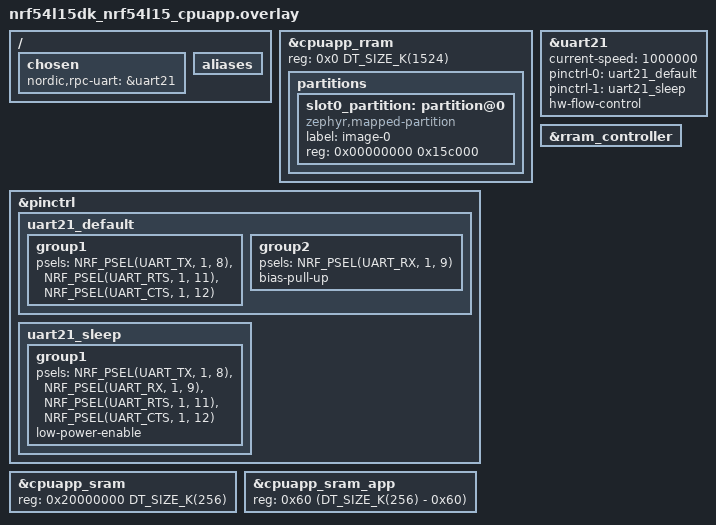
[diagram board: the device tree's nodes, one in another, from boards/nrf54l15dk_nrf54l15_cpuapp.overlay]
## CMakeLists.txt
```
#
# Copyright (c) 2026 Nordic Semiconductor ASA
#
# SPDX-License-Identifier: LicenseRef-Nordic-5-Clause
#

cmake_minimum_required(VERSION 3.20.0)

find_package(Zephyr REQUIRED HINTS $ENV{ZEPHYR_BASE})
project(dect_rpc)

target_sources(app PRIVATE src/main.c)
target_sources_ifdef(CONFIG_SAMPLE_DECT_RPC_CLIENT_IPERF3 app PRIVATE src/iperf3_shell.c)
```

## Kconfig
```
#
# Copyright (c) 2026 Nordic Semiconductor ASA
#
# SPDX-License-Identifier: LicenseRef-Nordic-5-Clause
#

menu "DECT NR+ RPC sample configuration"

config SAMPLE_DECT_RPC_CLIENT_IPERF3
	bool "iPerf3 (shell command)"
	select NRF_IPERF3
	help
	  Enable the ``iperf3`` shell command.

endmenu

source "Kconfig.zephyr"
```

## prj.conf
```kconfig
# DECT NR+ RPC sample — default role is client (no DECT modem on this device).
CONFIG_DECT_NR_RPC=y
CONFIG_DECT_NR_RPC_CLIENT=y
CONFIG_DECT_NR_RPC_NET_IF=y
CONFIG_NRF_RPC_UART_TRANSPORT=y
CONFIG_DECT_NR_RPC_UART_TRANSPORT=y

CONFIG_DECT_NR_RPC_CLIENT_IFACE_NAME="dect0"

# UART RPC RX ring (RAM). Use rpc-large-rx.conf (8 KiB) if bursts drop after connect.
CONFIG_NRF_RPC_UART_RX_RINGBUF_SIZE=4096

CONFIG_NRF_RPC_CBOR=y
CONFIG_NRF_RPC_ZCBOR_BACKUPS=1
CONFIG_NRF_RPC_THREAD_STACK_SIZE=4096
CONFIG_NRF_RPC_THREAD_PRIORITY=0

CONFIG_NRF_RPC_UART_RELIABLE=n
# 250 ms is too short for verbose "dect run sett -r" (many SHELL_LINE events + cmd RSP).
CONFIG_NRF_RPC_RESPONSE_TIMEOUT=400

# Client is follower: do not send group init; wait for server to send it.
CONFIG_NRF_RPC_GROUP_DEFAULT_INITIATOR=n
CONFIG_NRF_RPC_GROUP_INIT_WAIT_TIME=-1

CONFIG_UART_LINE_CTRL=y
CONFIG_UART_INTERRUPT_DRIVEN=y

# Networking
CONFIG_NETWORKING=y
CONFIG_NET_NATIVE=y
CONFIG_NET_IPV6=y
CONFIG_NET_MGMT_EVENT_STACK_SIZE=2048
CONFIG_NET_CONNECTION_MANAGER_MONITOR_STACK_SIZE=2048
CONFIG_DECT_NR_RPC_CONN_MGR=y
CONFIG_NET_IPV4=n
CONFIG_NET_SOCKETS=y
CONFIG_NET_SOCKETS_OFFLOAD=n
CONFIG_NET_MAX_CONN=6

CONFIG_NET_IF_UNICAST_IPV6_ADDR_COUNT=3
CONFIG_NET_IF_MAX_IPV6_COUNT=8
CONFIG_NET_INTERFACE_NAME=y

CONFIG_ZVFS_POLL_MAX=10

CONFIG_NET_BUF=y
CONFIG_NET_PKT_RX_COUNT=4
CONFIG_NET_BUF_RX_COUNT=8
CONFIG_NET_PKT_TX_COUNT=4
CONFIG_NET_BUF_TX_COUNT=8

CONFIG_HEAP_MEM_POOL_SIZE=2048

CONFIG_SHELL_STACK_SIZE=3072

# Optional: server.conf, dns.conf, ping.conf, iperf3-*.conf

CONFIG_LOG=y
CONFIG_NET_LOG=y
CONFIG_NRF_RPC_TR_LOG_LEVEL_INF=y
CONFIG_NRF_RPC_LOG_LEVEL_INF=y

CONFIG_SHELL=y
CONFIG_SHELL_PROMPT_UART="dect_rpc_client:~$ "
CONFIG_SHELL_BACKEND_SERIAL=y
CONFIG_NET_SHELL=y
CONFIG_DECT_NR_RPC_CLIENT_SHELL=y

CONFIG_LOG_BACKEND_UART=n
CONFIG_LOG_PRINTK=n

CONFIG_ASSERT=y
CONFIG_ASSERT_MODULE_DEFAULT_LEVEL_VERBOSE=y
CONFIG_RESET_ON_FATAL_ERROR=n
CONFIG_EXTRA_EXCEPTION_INFO=y
CONFIG_NET_DECT_RPC_LOG_LEVEL_INF=y
```

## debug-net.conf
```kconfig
# Extra Kconfig fragment: Zephyr net stack debug logging (RPC client).
#
# Build from this sample directory (see README):
#   west build -p -b nrf9151dk/nrf9151/ns -- -DEXTRA_CONF_FILE=debug-net.conf

CONFIG_NET_LOG=y
CONFIG_NET_CORE_LOG_LEVEL_DBG=y
CONFIG_NET_CONN_LOG_LEVEL_DBG=y
CONFIG_NET_SOCKETS_LOG_LEVEL_DBG=y
CONFIG_NET_IPV6_LOG_LEVEL_DBG=y
CONFIG_NET_ICMPV6_LOG_LEVEL_DBG=y
```

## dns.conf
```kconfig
# Unicast DNS resolver (optional). Not needed for literal IPv6 or RPC-only tests.
# Combine with ping.conf for hostname ping.
#
# CONFIG_DNS_SERVER1 must be reachable from dect0 (UDP/53 forwarded over RPC to the
# server DECT iface, then routed on the DECT network). Public resolvers (e.g. Google)
# only work if the DECT parent/BR provides internet routing. In many lab setups, set
# DNS_SERVER1 to your BR/DECT DNS instead. Verify with: net dns <name>

CONFIG_DNS_RESOLVER=y
CONFIG_DNS_RESOLVER_AUTO_INIT=y
CONFIG_DNS_SERVER_IP_ADDRESSES=y
CONFIG_DNS_SERVER1="2001:4860:4860::8888"
CONFIG_NET_SOCKETS_DNS_TIMEOUT=10000
CONFIG_NET_SOCKETS_DNS_BACKOFF_INTERVAL=4000
```

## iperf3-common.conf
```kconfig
# iperf3 common configuration.
# Build from this directory, e.g.:
#   west build -p -b nrf9151dk/nrf9151/ns -- -DEXTRA_CONF_FILE="iperf3-common.conf;iperf3-tx.conf"
#
# Disables DNS/mDNS and other extras not needed for raw throughput tests.

CONFIG_SAMPLE_DECT_RPC_CLIENT_IPERF3=y

# Throughput: avoid periodic GET_ADDRS on the same UART as IF_SEND; use 8 KiB RX ring.
CONFIG_DECT_NR_RPC_ADDR_SYNC_INTERVAL_SEC=0
CONFIG_NRF_RPC_UART_RX_RINGBUF_SIZE=8192

CONFIG_NRF_RPC_THREAD_POOL_SIZE=5
CONFIG_NRF_RPC_CMD_CTX_POOL_SIZE=12

CONFIG_DNS_RESOLVER=n
CONFIG_DNS_SD=n
CONFIG_DNS_RESOLVER_AUTO_INIT=n
CONFIG_DNS_RESOLVER_CACHE=n
CONFIG_DNS_SERVER_IP_ADDRESSES=n
CONFIG_MDNS_RESOLVER=n
CONFIG_MDNS_RESPONDER=n
CONFIG_MDNS_RESPONDER_DNS_SD=n
CONFIG_NET_SOCKETS_PACKET=n
CONFIG_NET_SOCKETS_PACKET_DGRAM=n
CONFIG_NET_SOCKETS_INET_RAW=n

CONFIG_NRF_IPERF3_HOST_NAME="nrf-dect-rpc-client-iperf3"
CONFIG_NRF_IPERF3_RESULTS_WAIT_TIME=180
CONFIG_NRF_IPERF3_NONBLOCKING_CLIENT_CHANGES=n

CONFIG_NET_IPV4=n
CONFIG_NET_IPV6=y
CONFIG_NET_IP_ADDR_CHECK=n
CONFIG_NET_IF_MAX_IPV6_COUNT=4

CONFIG_NET_TCP=y
CONFIG_NET_TCP_WORKQ_STACK_SIZE=2048
CONFIG_NET_TCP_INIT_RETRANSMISSION_TIMEOUT=6000
CONFIG_NET_TCP_RETRY_COUNT=6
CONFIG_NET_TCP_ISN_RFC6528=n

CONFIG_POSIX_API=y
CONFIG_GETOPT_LONG=y
CONFIG_CJSON_LIB=y
CONFIG_ZVFS_POLL_MAX=12
CONFIG_NET_MAX_CONTEXTS=10
CONFIG_NET_MAX_CONN=10

CONFIG_NET_CONTEXT_RCVTIMEO=y
CONFIG_NET_CONTEXT_SNDTIMEO=y

CONFIG_NET_BUF=y
CONFIG_NET_BUF_DATA_SIZE=128
CONFIG_NET_BUF_POOL_USAGE=y
CONFIG_NET_TC_RX_COUNT=0

# iperf3 uses libc malloc(); UART RPC TX uses k_malloc per frame (~header + CBOR + payload).
CONFIG_COMMON_LIBC_MALLOC_ARENA_SIZE=18432
CONFIG_HEAP_MEM_POOL_SIZE=24576
CONFIG_MAIN_STACK_SIZE=4096
CONFIG_SHELL_CMD_BUFF_SIZE=2048
# iperf_main() runs on the shell thread; default 2048 overflows (same as DeSh).
CONFIG_SHELL_STACK_SIZE=9216

CONFIG_SYS_HEAP_RUNTIME_STATS=y

CONFIG_NRF_RPC_TR_LOG_LEVEL_INF=y
CONFIG_NRF_RPC_LOG_LEVEL_WRN=y
CONFIG_NET_DECT_RPC_LOG_LEVEL_WRN=y
```

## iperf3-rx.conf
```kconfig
# iperf3 RX configuration (iperf server / downlink-heavy).
# Use after :file:`iperf3-common.conf`.

CONFIG_NRF_IPERF3_HOST_NAME="nrf-dect-rpc-client-iperf3-rx"

CONFIG_NET_BUF_DATA_SIZE=256
CONFIG_NET_PKT_RX_COUNT=22
CONFIG_NET_BUF_RX_COUNT=48
CONFIG_NET_PKT_TX_COUNT=16
CONFIG_NET_BUF_TX_COUNT=32

CONFIG_NET_TCP_RECV_QUEUE_TIMEOUT=10000
```

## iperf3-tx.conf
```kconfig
# iperf3 TX configuration (iperf client / uplink-heavy).
# Use after :file:`iperf3-common.conf`.

CONFIG_NRF_IPERF3_HOST_NAME="nrf-dect-rpc-client-iperf3-tx"

CONFIG_NET_BUF_DATA_SIZE=256
CONFIG_NET_PKT_RX_COUNT=10
CONFIG_NET_BUF_RX_COUNT=20
CONFIG_NET_PKT_TX_COUNT=30
CONFIG_NET_BUF_TX_COUNT=60
```

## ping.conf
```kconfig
# ICMPv6 ping shell (DECT_ICMP_PING_LIB).
#
# Build: west build ... -- -DEXTRA_CONF_FILE="ping.conf;dns.conf"
#
# Literal IPv6 targets work without dns.conf; hostnames need dns.conf.

CONFIG_GETOPT_LONG=y
CONFIG_DECT_ICMP_PING_LIB=y
CONFIG_DECT_ICMP_PING_DEFAULT_IFACE="dect0"

# getaddrinfo (dest + src) and shell command parsing
CONFIG_HEAP_MEM_POOL_SIZE=3072
CONFIG_SHELL_STACK_SIZE=4096
CONFIG_SYSTEM_WORKQUEUE_STACK_SIZE=2048

CONFIG_NET_STATISTICS=y
```

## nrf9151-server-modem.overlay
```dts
/*
 * Copyright (c) 2026 Nordic Semiconductor ASA
 *
 * SPDX-License-Identifier: LicenseRef-Nordic-5-Clause
 *
 * Server-only nRF9151 layout: modem IPC SHMEM and non-secure application RAM.
 * Apply on top of the default (client) board overlay when building server.conf:
 *
 *   -DEXTRA_DTC_OVERLAY_FILE=nrf9151-server-modem.overlay
 *
 * Flash partitions come from the default board overlay (client layout).
 */

/delete-node/ &sram0_s;
/delete-node/ &sram0_ns;

&sram0 {
	sram0_s: sram@0 {
		reg = <0x0 0x8000>;
	};

	sram0_ns: sram@8000 {
		reg = <0x8000 0x38000>;
		#address-cells = <1>;
		#size-cells = <1>;
		ranges = <0x0 0x8000 0x38000>;

		sram0_ns_modem: sram0_ns@0 {
			reg = <0x0 0x47a8>;
			#address-cells = <1>;
			#size-cells = <1>;
			ranges = <0x0 0x0 0x47a8>;

			cpuapp_cpucell_ipc_shm_ctrl: sram0_ns_modem@0 {
				reg = <0x0 0x728>;
			};

			cpuapp_cpucell_ipc_shm_heap: sram0_ns_modem@728 {
				reg = <0x728 0x2080>;
			};

			cpucell_cpuapp_ipc_shm_heap: sram0_ns_modem@27a8 {
				reg = <0x27a8 0x2000>;
			};
		};

		sram0_ns_app: sram0_ns@47a8 {
			reg = <0x47a8 0x33858>;
		};
	};
};
```

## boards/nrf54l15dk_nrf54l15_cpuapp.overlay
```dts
/*
 * Copyright (c) 2026 Nordic Semiconductor ASA
 *
 * SPDX-License-Identifier: LicenseRef-Nordic-5-Clause
 *
 * RPC over UART21 @ 1 Mbps with HW flow control (nRF RPC serialization reference).
 *
 * nRF54L15 DK (application core) UART21: RX P1.09, TX P1.08, RTS P1.11, CTS P1.12.
 * Cross-connect to nRF9151 DK server RPC UART (P0.10–P0.13).
 *
 * Frees GPIO used by UART21 by removing buttons 1–3 from devicetree.
 */

/ {
	chosen {
		nordic,rpc-uart = &uart21;
	};

	aliases {
		/delete-property/ sw1;
		/delete-property/ sw2;
		/delete-property/ sw3;
	};
};

/delete-node/ &button1;
/delete-node/ &button2;
/delete-node/ &button3;
/delete-node/ &boot_partition;
/delete-node/ &slot0_partition;
/delete-node/ &slot1_partition;

&cpuapp_rram {
	reg = <0x0 DT_SIZE_K(1524)>;

	partitions {
		slot0_partition: partition@0 {
			compatible = "zephyr,mapped-partition";
			label = "image-0";
			reg = <0x00000000 0x15c000>;
		};
	};
};

&pinctrl {
	uart21_default: uart21_default {
		group1 {
			psels = <NRF_PSEL(UART_TX, 1, 8)>,
				<NRF_PSEL(UART_RTS, 1, 11)>,
				<NRF_PSEL(UART_CTS, 1, 12)>;
		};

		group2 {
			psels = <NRF_PSEL(UART_RX, 1, 9)>;
			bias-pull-up;
		};
	};

	uart21_sleep: uart21_sleep {
		group1 {
			psels = <NRF_PSEL(UART_TX, 1, 8)>,
				<NRF_PSEL(UART_RX, 1, 9)>,
				<NRF_PSEL(UART_RTS, 1, 11)>,
				<NRF_PSEL(UART_CTS, 1, 12)>;
			low-power-enable;
		};
	};
};

&uart21 {
	status = "okay";
	current-speed = <1000000>;
	pinctrl-0 = <&uart21_default>;
	pinctrl-1 = <&uart21_sleep>;
	pinctrl-names = "default", "sleep";
	hw-flow-control;
};

&cpuapp_sram {
	reg = <0x20000000 DT_SIZE_K(256)>;
	ranges = <0x0 0x20000000 0x40000>;
};

&cpuapp_sram_app {
	reg = <0x60 (DT_SIZE_K(256) - 0x60)>;
};

&rram_controller {
	/delete-node/ cpuflpr_sram;
	/delete-node/ cpuflpr_rram;
};
```

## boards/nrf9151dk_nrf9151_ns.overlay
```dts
/*
 * Copyright (c) 2026 Nordic Semiconductor ASA
 *
 * SPDX-License-Identifier: LicenseRef-Nordic-5-Clause
 *
 * RPC over UART1.
 *
 * Pins: RX P0.10, TX P0.11, CTS P0.12, RTS P0.13 (cross TX-RX and RTS-CTS to peer).
 *
 * Flash layout without MCUboot (960 kB non-secure app region); required with
 * PARTITION_MANAGER=n because the default nrf91xx slot0_ns is only 192 kB.
 */

#include <samples/cellular/nrf91_no_bootloader_partitions.dtsi>

/ {
	chosen {
		nordic,rpc-uart = &uart1;
	};
};

&uart1 {
	compatible = "nordic,nrf-uarte";
	status = "okay";
	current-speed = <1000000>;
	hw-flow-control;

	pinctrl-0 = <&uart1_default_alt>;
	pinctrl-1 = <&uart1_sleep_alt>;
	pinctrl-names = "default", "sleep";
};

&pinctrl {
	uart1_default_alt: uart1_default_alt {
		group1 {
			psels = <NRF_PSEL(UART_RX, 0, 10)>,
				<NRF_PSEL(UART_CTS, 0, 12)>;
			bias-pull-up;
		};

		group2 {
			psels = <NRF_PSEL(UART_TX, 0, 11)>,
				<NRF_PSEL(UART_RTS, 0, 13)>;
		};
	};

	uart1_sleep_alt: uart1_sleep_alt {
		group1 {
			psels = <NRF_PSEL(UART_RX, 0, 10)>,
				<NRF_PSEL(UART_TX, 0, 11)>,
				<NRF_PSEL(UART_CTS, 0, 12)>,
				<NRF_PSEL(UART_RTS, 0, 13)>;
			low-power-enable;
		};
	};
};
```

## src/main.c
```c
/*
 * Copyright (c) 2026 Nordic Semiconductor ASA
 *
 * SPDX-License-Identifier: LicenseRef-Nordic-5-Clause
 *
 * DECT NR+ RPC sample: client or server role (see prj.conf / server.conf).
 */

#include <zephyr/kernel.h>
#include <zephyr/net/net_if.h>
#include <zephyr/logging/log.h>

LOG_MODULE_REGISTER(main, LOG_LEVEL_INF);

#if defined(CONFIG_DECT_NR_RPC_SERVER)

#include <zephyr/net/net_core.h>
#include <nrf_modem.h>
#include <modem/nrf_modem_lib.h>
#include <nrf_rpc.h>

static void rpc_err_handler(const struct nrf_rpc_err_report *report)
{
	LOG_ERR("RPC error: %d", report->code);
}

static const char *modem_fault_reason_str(uint32_t reason)
{
	switch (reason) {
	case NRF_MODEM_FAULT_UNDEFINED:
		return "Undefined fault";
	case NRF_MODEM_FAULT_HW_WD_RESET:
		return "HW WD reset";
	case NRF_MODEM_FAULT_HARDFAULT:
		return "Hard fault";
	case NRF_MODEM_FAULT_MEM_MANAGE:
		return "Memory management fault";
	case NRF_MODEM_FAULT_BUS:
		return "Bus fault";
	case NRF_MODEM_FAULT_USAGE:
		return "Usage fault";
	case NRF_MODEM_FAULT_SECURE_RESET:
		return "Secure control reset";
	case NRF_MODEM_FAULT_PANIC_DOUBLE:
		return "Error handler crash";
	case NRF_MODEM_FAULT_PANIC_RESET_LOOP:
		return "Reset loop";
	case NRF_MODEM_FAULT_ASSERT:
		return "Assert";
	case NRF_MODEM_FAULT_PANIC:
		return "Unconditional SW reset";
	case NRF_MODEM_FAULT_FLASH_ERASE:
		return "Flash erase fault";
	case NRF_MODEM_FAULT_FLASH_WRITE:
		return "Flash write fault";
	case NRF_MODEM_FAULT_POFWARN:
		return "Undervoltage fault";
	case NRF_MODEM_FAULT_THWARN:
		return "Overtemperature fault";
	default:
		return "Unknown reason";
	}
}

void nrf_modem_fault_handler(struct nrf_modem_fault_info *fault_info)
{
	LOG_ERR("Modem fault: reason=0x%x (%s), PC=0x%x",
		fault_info->reason,
		modem_fault_reason_str(fault_info->reason),
		fault_info->program_counter);

	__ASSERT(false, "Modem crash detected, halting application");
}

int main(void)
{
	int err;

	LOG_INF("DECT RPC server running. DECT interface receives/sends via RPC.");

	err = nrf_modem_lib_init();
	if (err) {
		LOG_ERR("nrf_modem_lib_init failed: %d", err);
		return err;
	}
	LOG_INF("nRF Modem library initialized");

	LOG_INF("Initializing RPC...");
	err = nrf_rpc_init(rpc_err_handler);
	if (err != 0) {
		LOG_ERR("nrf_rpc_init failed: %d", err);
		return err;
	}
	LOG_INF("RPC initialized");

	return 0;
}

#elif defined(CONFIG_DECT_NR_RPC_CLIENT)

#include <nrf_rpc.h>

#include <net/dect/dect_rpc.h>

#if defined(CONFIG_DECT_NR_RPC_CONN_MGR)
#include <zephyr/net/net_event.h>
#include <zephyr/net/net_mgmt.h>
#endif

#if !defined(CONFIG_NRF_RPC_INIT)
static void rpc_err_handler(const struct nrf_rpc_err_report *report)
{
	LOG_ERR("RPC error: %d", report->code);
}

static K_SEM_DEFINE(rpc_bound_sem, 0, 1);

static void bound_handler(const struct nrf_rpc_group *group)
{
	if (group == dect_rpc_client_get_group()) {
		k_sem_give(&rpc_bound_sem);
	}
}
#endif

#if defined(CONFIG_DECT_NR_RPC_CONN_MGR)
static struct net_if *rpc_client_iface;
static struct net_mgmt_event_callback rpc_if_evt_cb;
static struct net_mgmt_event_callback rpc_l4_evt_cb;

static void rpc_if_event_handler(struct net_mgmt_event_callback *cb, uint64_t mgmt_event,
				 struct net_if *iface)
{
	if (iface != rpc_client_iface) {
		return;
	}

	switch (mgmt_event) {
	case NET_EVENT_IF_UP:
		LOG_INF("NET_EVENT_IF_UP");
		break;
	case NET_EVENT_IF_DOWN:
		LOG_INF("NET_EVENT_IF_DOWN");
		break;
	case NET_EVENT_IF_ADMIN_UP:
		LOG_INF("NET_EVENT_IF_ADMIN_UP");
		break;
	case NET_EVENT_IF_ADMIN_DOWN:
		LOG_INF("NET_EVENT_IF_ADMIN_DOWN");
		break;
	default:
		break;
	}
}

static void rpc_l4_event_handler(struct net_mgmt_event_callback *cb, uint64_t mgmt_event,
				 struct net_if *iface)
{
	if (iface != rpc_client_iface) {
		return;
	}

	switch (mgmt_event) {
	case NET_EVENT_L4_CONNECTED:
		LOG_INF("NET_EVENT_L4_CONNECTED");
		break;
	case NET_EVENT_L4_DISCONNECTED:
		LOG_INF("NET_EVENT_L4_DISCONNECTED");
		break;
	case NET_EVENT_L4_IPV6_CONNECTED:
		LOG_INF("NET_EVENT_L4_IPV6_CONNECTED");
		break;
	case NET_EVENT_L4_IPV6_DISCONNECTED:
		LOG_INF("NET_EVENT_L4_IPV6_DISCONNECTED");
		break;
	default:
		break;
	}
}

static void rpc_client_net_events_register(void)
{
	int idx = net_if_get_by_name(CONFIG_DECT_NR_RPC_CLIENT_IFACE_NAME);

	if (idx < 0) {
		return;
	}

	rpc_client_iface = net_if_get_by_index(idx);

	net_mgmt_init_event_callback(&rpc_if_evt_cb, rpc_if_event_handler,
				     NET_EVENT_IF_UP | NET_EVENT_IF_DOWN | NET_EVENT_IF_ADMIN_UP |
					     NET_EVENT_IF_ADMIN_DOWN);
	net_mgmt_add_event_callback(&rpc_if_evt_cb);

	net_mgmt_init_event_callback(&rpc_l4_evt_cb, rpc_l4_event_handler,
				     NET_EVENT_L4_CONNECTED | NET_EVENT_L4_DISCONNECTED |
					     NET_EVENT_L4_IPV6_CONNECTED |
					     NET_EVENT_L4_IPV6_DISCONNECTED);
	net_mgmt_add_event_callback(&rpc_l4_evt_cb);
}
#endif /* CONFIG_DECT_NR_RPC_CONN_MGR */

int main(void)
{
#if !defined(CONFIG_NRF_RPC_INIT)
	nrf_rpc_set_bound_handler(bound_handler);
	LOG_INF("Initializing RPC...");
	int err;

	err = nrf_rpc_init(rpc_err_handler);
	if (err != 0) {
		LOG_ERR("nrf_rpc_init failed: %d", err);
		return err;
	}
	LOG_INF("Waiting for server... (start server now)");
	if (k_sem_take(&rpc_bound_sem, K_MSEC(15000)) != 0) {
		LOG_ERR("Timeout waiting for RPC group (server not connected?)");
		return -ETIMEDOUT;
	}
	LOG_INF("RPC initialized (server ready)");
	dect_rpc_client_notify_rpc_init_done();
#endif

	if (net_if_get_by_name(CONFIG_DECT_NR_RPC_CLIENT_IFACE_NAME) < 0) {
		LOG_ERR("No DECT RPC interface named \"%s\" (CONFIG_NET_INTERFACE_NAME?)",
			CONFIG_DECT_NR_RPC_CLIENT_IFACE_NAME);
		return -ENOENT;
	}

#if defined(CONFIG_DECT_NR_RPC_CONN_MGR)
	rpc_client_net_events_register();
#endif

#if defined(CONFIG_DECT_NR_RPC_AUTO_SYNC)
	LOG_INF("DECT RPC client running. %s starts admin-down; after RPC init, auto-sync "
		"pulls addresses from the server and brings the iface up (~%d s, or run "
		"dect sync)",
		CONFIG_DECT_NR_RPC_CLIENT_IFACE_NAME, CONFIG_DECT_NR_RPC_AUTO_SYNC_DELAY_SEC);
#else
	LOG_INF("DECT RPC client running. %s uses NO_AUTO_START; run dect sync then "
		"net if up %s",
		CONFIG_DECT_NR_RPC_CLIENT_IFACE_NAME, CONFIG_DECT_NR_RPC_CLIENT_IFACE_NAME);
#endif
#if defined(CONFIG_DECT_NR_RPC_CONN_MGR)
	LOG_INF("Use dect connect / dect disconnect for DECT association on the server");
#endif
#if defined(CONFIG_NET_HOSTNAME_ENABLE)
	LOG_INF("mDNS name: %s.local (resolve from server or other hosts on link)",
		CONFIG_NET_HOSTNAME);
#endif

	return 0;
}

#else
#error "Build with default prj.conf (client) or EXTRA_CONF_FILE=server.conf"
#endif
```

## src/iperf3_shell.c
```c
/*
 * Copyright (c) 2026 Nordic Semiconductor ASA
 *
 * SPDX-License-Identifier: LicenseRef-Nordic-5-Clause
 */

#include <zephyr/shell/shell.h>
#include <zephyr/posix/sys/select.h>
#include <iperf_api.h>

static int cmd_iperf3(const struct shell *shell, size_t argc, char **argv)
{
	ARG_UNUSED(shell);

	(void)iperf_main(argc, argv, NULL, 0, NULL);
	return 0;
}

SHELL_CMD_REGISTER(iperf3, NULL, "iPerf3 (try: iperf3 --manual)", cmd_iperf3);
```
